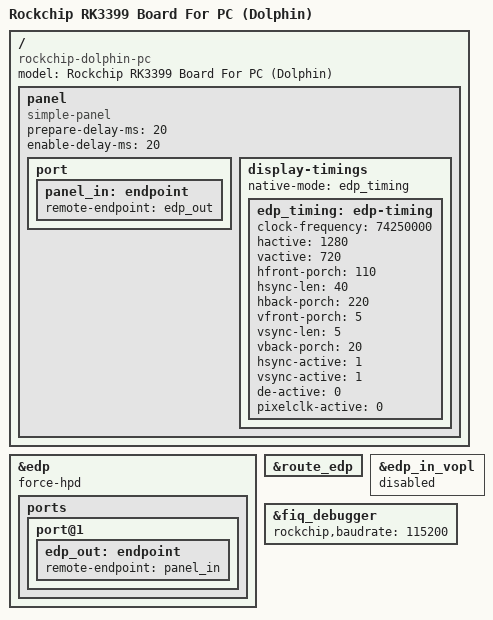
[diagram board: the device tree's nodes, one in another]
/*
 * Copyright (c) 2016 Fuzhou Rockchip Electronics Co., Ltd
 *
 * This file is dual-licensed: you can use it either under the terms
 * of the GPL or the X11 license, at your option. Note that this dual
 * licensing only applies to this file, and not this project as a
 * whole.
 *
 *  a) This file is free software; you can redistribute it and/or
 *     modify it under the terms of the GNU General Public License as
 *     published by the Free Software Foundation; either version 2 of the
 *     License, or (at your option) any later version.
 *
 *     This file is distributed in the hope that it will be useful,
 *     but WITHOUT ANY WARRANTY; without even the implied warranty of
 *     MERCHANTABILITY or FITNESS FOR A PARTICULAR PURPOSE.  See the
 *     GNU General Public License for more details.
 *
 * Or, alternatively,
 *
 *  b) Permission is hereby granted, free of charge, to any person
 *     obtaining a copy of this software and associated documentation
 *     files (the "Software"), to deal in the Software without
 *     restriction, including without limitation the rights to use,
 *     copy, modify, merge, publish, distribute, sublicense, and/or
 *     sell copies of the Software, and to permit persons to whom the
 *     Software is furnished to do so, subject to the following
 *     conditions:
 *
 *     The above copyright notice and this permission notice shall be
 *     included in all copies or substantial portions of the Software.
 *
 *     THE SOFTWARE IS PROVIDED "AS IS", WITHOUT WARRANTY OF ANY KIND,
 *     EXPRESS OR IMPLIED, INCLUDING BUT NOT LIMITED TO THE WARRANTIES
 *     OF MERCHANTABILITY, FITNESS FOR A PARTICULAR PURPOSE AND
 *     NONINFRINGEMENT. IN NO EVENT SHALL THE AUTHORS OR COPYRIGHT
 *     HOLDERS BE LIABLE FOR ANY CLAIM, DAMAGES OR OTHER LIABILITY,
 *     WHETHER IN AN ACTION OF CONTRACT, TORT OR OTHERWISE, ARISING
 *     FROM, OUT OF OR IN CONNECTION WITH THE SOFTWARE OR THE USE OR
 *     OTHER DEALINGS IN THE SOFTWARE.
 */

/dts-v1/;
#include "rk3399-dolphin.dtsi"

/ {
	model = "Rockchip RK3399 Board For PC (Dolphin)";
	compatible = "rockchip-dolphin-pc","rockchip,rk3399-dolphin";

	panel: panel {
		status = "okay";
		compatible = "simple-panel";
		prepare-delay-ms = <20>;
		enable-delay-ms = <20>;
	
		port {
			panel_in: endpoint {
				remote-endpoint = <&edp_out>;
			};
		};

		display-timings {
			native-mode = <&edp_timing>;
	
			edp_timing: edp-timing {
				clock-frequency = <74250000>;
				hactive = <1280>;
				vactive = <720>;
				hfront-porch = <110>;
				hsync-len = <40>;
				hback-porch = <220>;
				vfront-porch = <5>;
				vsync-len = <5>;
				vback-porch = <20>;
				hsync-active = <1>;
				vsync-active = <1>;
				de-active = <0>;
				pixelclk-active = <0>;
			};
		};
	};
};

&edp {
	status = "okay";
	force-hpd;
	ports {
		port@1 {
			edp_out: endpoint {
				remote-endpoint = <&panel_in>;
			};
		};
	};
};

&route_edp {
	status = "okay";
};

&edp_in_vopl {
        status = "disabled";
};

&fiq_debugger {
	rockchip,baudrate = <115200>;
};
